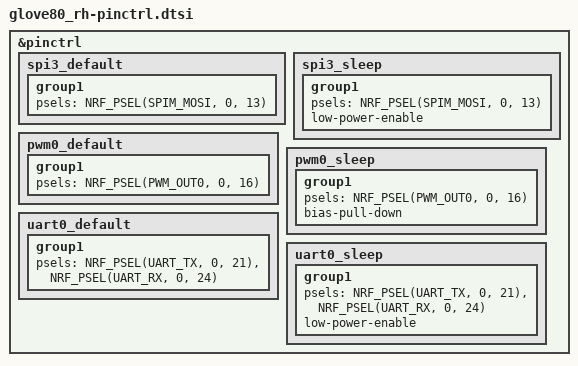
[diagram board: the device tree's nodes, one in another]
/*
 * Copyright (c) 2021 The ZMK Contributors
 * SPDX-License-Identifier: MIT
 */

&pinctrl {
    spi3_default: spi3_default {
        group1 {
            psels = <NRF_PSEL(SPIM_MOSI, 0, 13)>; // WS2812_VEXT_DATA
        };
    };

    spi3_sleep: spi3_sleep {
        group1 {
            psels = <NRF_PSEL(SPIM_MOSI, 0, 13)>;
            low-power-enable;
        };
    };

    pwm0_default: pwm0_default {
        group1 {
            psels = <NRF_PSEL(PWM_OUT0, 0, 16)>; // Rear LED
        };
    };

    pwm0_sleep: pwm0_sleep {
        group1 {
            psels = <NRF_PSEL(PWM_OUT0, 0, 16)>;
            bias-pull-down;
        };
    };

    uart0_default: uart0_default {
        group1 {
            psels = <NRF_PSEL(UART_TX, 0, 21)>, // EXT1
                    <NRF_PSEL(UART_RX, 0, 24)>;  // EXT2
        };
    };

    uart0_sleep: uart0_sleep {
        group1 {
            psels = <NRF_PSEL(UART_TX, 0, 21)>,
                    <NRF_PSEL(UART_RX, 0, 24)>;
            low-power-enable;
        };
    };

};
